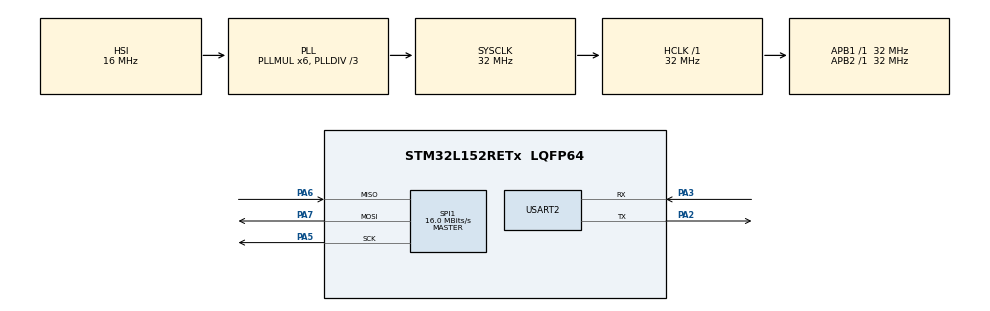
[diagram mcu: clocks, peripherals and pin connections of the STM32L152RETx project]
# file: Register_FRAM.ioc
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Mcu.Family=STM32L1
Mcu.Name=STM32L152RETx
Mcu.Package=LQFP64
NVIC.PriorityGroup=NVIC_PRIORITYGROUP_0
PA2.Mode=Asynchronous
PA2.Signal=USART2_TX
PA3.Mode=Asynchronous
PA3.Signal=USART2_RX
PA5.Mode=Full_Duplex_Master
PA5.Signal=SPI1_SCK
PA6.Mode=Full_Duplex_Master
PA6.Signal=SPI1_MISO
PA7.Mode=Full_Duplex_Master
PA7.Signal=SPI1_MOSI
ProjectManager.HeapSize=0x200
ProjectManager.StackSize=0x400
ProjectManager.TargetToolchain=MDK-ARM V5
RCC.48MHZClocksFreq_Value=48000000
RCC.AHBFreq_Value=32000000
RCC.APB1Freq_Value=32000000
RCC.APB1TimFreq_Value=32000000
RCC.APB2Freq_Value=32000000
RCC.APB2TimFreq_Value=32000000
RCC.HCLKFreq_Value=32000000
RCC.HSE_VALUE=8000000
RCC.HSI_VALUE=16000000
RCC.LSE_VALUE=32768
RCC.MSI_VALUE=2097000
RCC.PLLDIV=RCC_PLL_DIV3
RCC.PLLMUL=RCC_PLL_MUL6
RCC.RTCClockSelectionVirtual=RCC_RTCCLKSOURCE_LSE
RCC.SYSCLKFreq_VALUE=32000000
RCC.SYSCLKSource=RCC_SYSCLKSOURCE_PLLCLK
RCC.USBOutput=48000000
RCC.VCOOutputFreq_Value=96000000
SPI1.BaudRatePrescaler=SPI_BAUDRATEPRESCALER_2
SPI1.CalculateBaudRate=16.0 MBits/s
SPI1.Direction=SPI_DIRECTION_2LINES
SPI1.Mode=SPI_MODE_MASTER
SPI1.VirtualType=VM_MASTER
USART2.VirtualMode=VM_ASYNC
board=NUCLEO-L152RE

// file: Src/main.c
/* USER CODE BEGIN Header */
/**
  ******************************************************************************
  * @file           : main.c
  * @brief          : Main program body
  ******************************************************************************
  ** This notice applies to any and all portions of this file
  * that are not between comment pairs USER CODE BEGIN and
  * USER CODE END. Other portions of this file, whether
  * inserted by the user or by software development tools
  * are owned by their respective copyright owners.
  *
  * COPYRIGHT(c) 2019 STMicroelectronics
  *
  * Redistribution and use in source and binary forms, with or without modification,
  * are permitted provided that the following conditions are met:
  *   1. Redistributions of source code must retain the above copyright notice,
  *      this list of conditions and the following disclaimer.
  *   2. Redistributions in binary form must reproduce the above copyright notice,
  *      this list of conditions and the following disclaimer in the documentation
  *      and/or other materials provided with the distribution.
  *   3. Neither the name of STMicroelectronics nor the names of its contributors
  *      may be used to endorse or promote products derived from this software
  *      without specific prior written permission.
  *
  * THIS SOFTWARE IS PROVIDED BY THE COPYRIGHT HOLDERS AND CONTRIBUTORS "AS IS"
  * AND ANY EXPRESS OR IMPLIED WARRANTIES, INCLUDING, BUT NOT LIMITED TO, THE
  * IMPLIED WARRANTIES OF MERCHANTABILITY AND FITNESS FOR A PARTICULAR PURPOSE ARE
  * DISCLAIMED. IN NO EVENT SHALL THE COPYRIGHT HOLDER OR CONTRIBUTORS BE LIABLE
  * FOR ANY DIRECT, INDIRECT, INCIDENTAL, SPECIAL, EXEMPLARY, OR CONSEQUENTIAL
  * DAMAGES (INCLUDING, BUT NOT LIMITED TO, PROCUREMENT OF SUBSTITUTE GOODS OR
  * SERVICES; LOSS OF USE, DATA, OR PROFITS; OR BUSINESS INTERRUPTION) HOWEVER
  * CAUSED AND ON ANY THEORY OF LIABILITY, WHETHER IN CONTRACT, STRICT LIABILITY,
  * OR TORT (INCLUDING NEGLIGENCE OR OTHERWISE) ARISING IN ANY WAY OUT OF THE USE
  * OF THIS SOFTWARE, EVEN IF ADVISED OF THE POSSIBILITY OF SUCH DAMAGE.
  *
  ******************************************************************************
  */
/* USER CODE END Header */

#include "main.h"

/* USER CODE BEGIN Includes */
#include "SPI_FRAM.h"
#include "string.h"

/* USER CODE END Includes */

SPI_HandleTypeDef hspi1;

UART_HandleTypeDef huart2;

void SystemClock_Config(void);
static void MX_GPIO_Init(void);
static void MX_SPI1_Init(void);
static void MX_USART2_UART_Init(void);

int main(void)
{

  /* MCU Configuration--------------------------------------------------------*/

  /* Reset of all peripherals, Initializes the Flash interface and the Systick. */
  HAL_Init();

  /* Configure the system clock */
  SystemClock_Config();

  /* Initialize all configured peripherals */
  MX_GPIO_Init();
  MX_SPI1_Init();
  MX_USART2_UART_Init();
  /* USER CODE BEGIN 2 */

	unsigned char SUCCESS[] = "Success\n";
	unsigned char ERROR[] = "Fail\n";
	uint8_t data[101] = {0};
	uint8_t Readdata[101] = {0};
	 for(int i =0;i<100;i++){
				data[i]=1;
				Readdata[i]=2;
	 }
	uint8_t correct = 0;
	char Msg1[100] = {0};
	char Msg2[100] = {0};

	snprintf((char *)Msg1, sizeof(Msg1), "\n\nSTARTING THE CC1200 TRANSCEIVER TEST\n\n");
	HAL_UART_Transmit(&huart2, (uint8_t *) Msg1, sizeof(Msg1), 1);
	memcpy(Msg1, Msg2, 100);

	SPI_FRAM_Write(hspi1,time,data,100);
	SPI_FRAM_Read(hspi1, time, Readdata,100);
	//Readdata[77]=8;

   for(int i =0;i<100;i++){
			if(data[i]==Readdata[i]){
				correct++;
			}
	 }
  snprintf((char *)Msg1, sizeof(Msg1), "\n  %d / 100  correct\n",correct);
	HAL_UART_Transmit(&huart2, (uint8_t *) Msg1, sizeof(Msg1), 1);
	memcpy(Msg1, Msg2, 100);

  /* USER CODE END 2 */

  /* Infinite loop */
  while (1)
  {

  }
}

void SystemClock_Config(void)
{
  RCC_OscInitTypeDef RCC_OscInitStruct = {0};
  RCC_ClkInitTypeDef RCC_ClkInitStruct = {0};

  /**Configure the main internal regulator output voltage
  */
  __HAL_PWR_VOLTAGESCALING_CONFIG(PWR_REGULATOR_VOLTAGE_SCALE1);
  /**Initializes the CPU, AHB and APB busses clocks
  */
  RCC_OscInitStruct.OscillatorType = RCC_OSCILLATORTYPE_HSI;
  RCC_OscInitStruct.HSIState = RCC_HSI_ON;
  RCC_OscInitStruct.HSICalibrationValue = RCC_HSICALIBRATION_DEFAULT;
  RCC_OscInitStruct.PLL.PLLState = RCC_PLL_ON;
  RCC_OscInitStruct.PLL.PLLSource = RCC_PLLSOURCE_HSI;
  RCC_OscInitStruct.PLL.PLLMUL = RCC_PLL_MUL6;
  RCC_OscInitStruct.PLL.PLLDIV = RCC_PLL_DIV3;
  if (HAL_RCC_OscConfig(&RCC_OscInitStruct) != HAL_OK)
  {
    Error_Handler();
  }
  /**Initializes the CPU, AHB and APB busses clocks
  */
  RCC_ClkInitStruct.ClockType = RCC_CLOCKTYPE_HCLK|RCC_CLOCKTYPE_SYSCLK
                              |RCC_CLOCKTYPE_PCLK1|RCC_CLOCKTYPE_PCLK2;
  RCC_ClkInitStruct.SYSCLKSource = RCC_SYSCLKSOURCE_PLLCLK;
  RCC_ClkInitStruct.AHBCLKDivider = RCC_SYSCLK_DIV1;
  RCC_ClkInitStruct.APB1CLKDivider = RCC_HCLK_DIV1;
  RCC_ClkInitStruct.APB2CLKDivider = RCC_HCLK_DIV1;

  if (HAL_RCC_ClockConfig(&RCC_ClkInitStruct, FLASH_LATENCY_1) != HAL_OK)
  {
    Error_Handler();
  }
}

static void MX_SPI1_Init(void)
{

  /* SPI1 parameter configuration*/
  hspi1.Instance = SPI1;
  hspi1.Init.Mode = SPI_MODE_MASTER;
  hspi1.Init.Direction = SPI_DIRECTION_2LINES;
  hspi1.Init.DataSize = SPI_DATASIZE_8BIT;
  hspi1.Init.CLKPolarity = SPI_POLARITY_LOW;
  hspi1.Init.CLKPhase = SPI_PHASE_1EDGE;
  hspi1.Init.NSS = SPI_NSS_SOFT;
  hspi1.Init.BaudRatePrescaler = SPI_BAUDRATEPRESCALER_2;
  hspi1.Init.FirstBit = SPI_FIRSTBIT_MSB;
  hspi1.Init.TIMode = SPI_TIMODE_DISABLE;
  hspi1.Init.CRCCalculation = SPI_CRCCALCULATION_DISABLE;
  hspi1.Init.CRCPolynomial = 10;
  if (HAL_SPI_Init(&hspi1) != HAL_OK)
  {
    Error_Handler();
  }

}

static void MX_USART2_UART_Init(void)
{

  huart2.Instance = USART2;
  huart2.Init.BaudRate = 115200;
  huart2.Init.WordLength = UART_WORDLENGTH_8B;
  huart2.Init.StopBits = UART_STOPBITS_1;
  huart2.Init.Parity = UART_PARITY_NONE;
  huart2.Init.Mode = UART_MODE_TX_RX;
  huart2.Init.HwFlowCtl = UART_HWCONTROL_NONE;
  huart2.Init.OverSampling = UART_OVERSAMPLING_16;
  if (HAL_UART_Init(&huart2) != HAL_OK)
  {
    Error_Handler();
  }

}

static void MX_GPIO_Init(void)
{
  GPIO_InitTypeDef GPIO_InitStruct = {0};

  /* GPIO Ports Clock Enable */
  __HAL_RCC_GPIOA_CLK_ENABLE();

  /*Configure GPIO pin Output Level */
  HAL_GPIO_WritePin(GPIOA, GPIO_PIN_9, GPIO_PIN_RESET);

  /*Configure GPIO pin : PA9 */
  GPIO_InitStruct.Pin = GPIO_PIN_9;
  GPIO_InitStruct.Mode = GPIO_MODE_OUTPUT_PP;
  GPIO_InitStruct.Pull = GPIO_NOPULL;
  GPIO_InitStruct.Speed = GPIO_SPEED_FREQ_LOW;
  HAL_GPIO_Init(GPIOA, &GPIO_InitStruct);

}

void Error_Handler(void)
{
}

/************************ (C) COPYRIGHT STMicroelectronics *****END OF FILE****/
